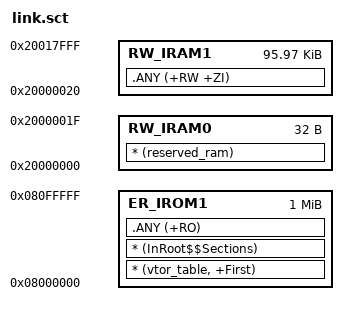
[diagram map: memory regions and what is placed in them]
; *************************************************************
; *** Scatter-Loading Description File generated by uVision ***
; *************************************************************

LR_IROM1 0x08000000 0x00100000  {    ; load region size_region
  ER_IROM1 0x08000000 0x00100000  {  ; load address = execution address
   * (vtor_table, +First)
   * (InRoot$$Sections)
   .ANY (+RO)
  }

  RW_IRAM0 0x20000000 0x20  {  ; RW data
   * (reserved_ram)
  }

  RW_IRAM1 0x20000020 0x17fe0  {  ; RW data
   .ANY (+RW +ZI)
  }
}

